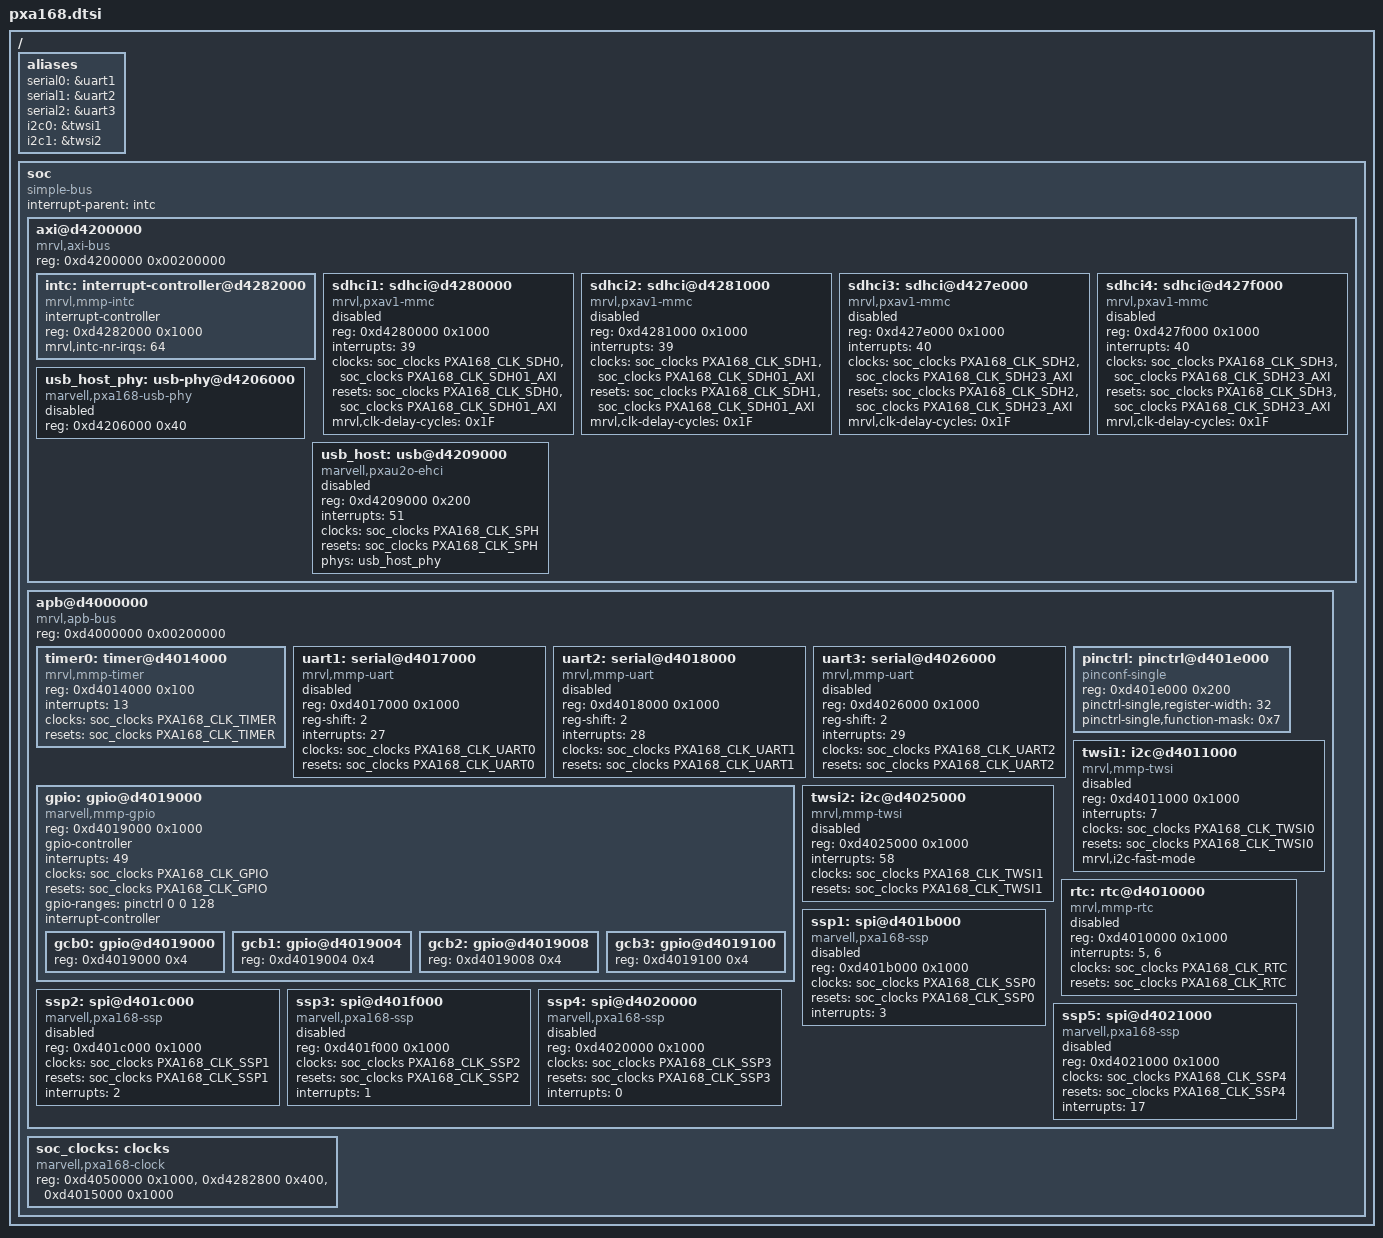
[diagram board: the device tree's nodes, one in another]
// SPDX-License-Identifier: GPL-2.0-only
/*
 *  Copyright (C) 2012 Marvell Technology Group Ltd.
 *  Author: Haojian Zhuang <haojian.zhuang@marvell.com>
 */

#include <dt-bindings/clock/marvell,pxa168.h>

#define MFP_PIN_PXA168(gpio)				\
	((gpio <= 36) ? (0x004c + 4 * gpio) :		\
	 (gpio <= 55) ? (0x0000 + 4 * (gpio - 37)) :	\
	 (gpio <= 122) ? (0x00e0 + 4 * (gpio - 56)) :	\
	 0)

#define MFP_AF0		(0 << 0)
#define MFP_AF1		(1 << 0)
#define MFP_AF2		(2 << 0)
#define MFP_AF3		(3 << 0)
#define MFP_AF4		(4 << 0)
#define MFP_AF5		(5 << 0)
#define MFP_AF6		(6 << 0)
#define MFP_AF7		(7 << 0)

#define MFP_DSMSK	(0x3 << 10)
#define MFP_DS01X	< (0x0 << 10) MFP_DSMSK >
#define MFP_DS02X	< (0x1 << 10) MFP_DSMSK >
#define MFP_DS03X	< (0x2 << 10) MFP_DSMSK >
#define MFP_DS04X	< (0x3 << 10) MFP_DSMSK >

#define MPF_PULL_MSK	(0x7 << 13)
#define MPF_PULL_DOWN	< (0x5 << 13) (0x5 << 13) 0 MPF_PULL_MSK >
#define MPF_PULL_UP	< (0x6 << 13) (0x6 << 13) 0 MPF_PULL_MSK >

/* TODO: MFP60 through MFP62's drive strength bits have special meaning for voltage control
 * MFP56 through MFP59's drive strength bits control all of MFP56 through MFP85 */

/ {
	#address-cells = <1>;
	#size-cells = <1>;

	aliases {
		serial0 = &uart1;
		serial1 = &uart2;
		serial2 = &uart3;
		i2c0 = &twsi1;
		i2c1 = &twsi2;
	};

	soc {
		#address-cells = <1>;
		#size-cells = <1>;
		compatible = "simple-bus";
		interrupt-parent = <&intc>;
		ranges;

		axi@d4200000 {	/* AXI */
			compatible = "mrvl,axi-bus", "simple-bus";
			#address-cells = <1>;
			#size-cells = <1>;
			reg = <0xd4200000 0x00200000>;
			ranges;

			intc: interrupt-controller@d4282000 {
				compatible = "mrvl,mmp-intc";
				interrupt-controller;
				#interrupt-cells = <1>;
				reg = <0xd4282000 0x1000>;
				mrvl,intc-nr-irqs = <64>;
			};

			sdhci1: sdhci@d4280000 {
				compatible = "mrvl,pxav1-mmc";
				reg = <0xd4280000 0x1000>;
				interrupts = <39>;
				clocks = <&soc_clocks PXA168_CLK_SDH0>,
					 <&soc_clocks PXA168_CLK_SDH01_AXI>;
				resets = <&soc_clocks PXA168_CLK_SDH0>,
					 <&soc_clocks PXA168_CLK_SDH01_AXI>;
				clock-names = "io", "core";
				mrvl,clk-delay-cycles = <0x1F>;
				status = "disabled";
			};

			sdhci2: sdhci@d4281000 {
				compatible = "mrvl,pxav1-mmc";
				reg = <0xd4281000 0x1000>;
				interrupts = <39>;
				clocks = <&soc_clocks PXA168_CLK_SDH1>,
					 <&soc_clocks PXA168_CLK_SDH01_AXI>;
				resets = <&soc_clocks PXA168_CLK_SDH1>,
					 <&soc_clocks PXA168_CLK_SDH01_AXI>;
				clock-names = "io", "core";
				mrvl,clk-delay-cycles = <0x1F>;
				status = "disabled";
			};

			sdhci3: sdhci@d427e000 {
				compatible = "mrvl,pxav1-mmc";
				reg = <0xd427e000 0x1000>;
				interrupts = <40>;
				clocks = <&soc_clocks PXA168_CLK_SDH2>,
					 <&soc_clocks PXA168_CLK_SDH23_AXI>;
				resets = <&soc_clocks PXA168_CLK_SDH2>,
					 <&soc_clocks PXA168_CLK_SDH23_AXI>;
				clock-names = "io", "core";
				mrvl,clk-delay-cycles = <0x1F>;
				status = "disabled";
			};

			sdhci4: sdhci@d427f000 {
				compatible = "mrvl,pxav1-mmc";
				reg = <0xd427f000 0x1000>;
				interrupts = <40>;
				clocks = <&soc_clocks PXA168_CLK_SDH3>,
					 <&soc_clocks PXA168_CLK_SDH23_AXI>;
				resets = <&soc_clocks PXA168_CLK_SDH3>,
					 <&soc_clocks PXA168_CLK_SDH23_AXI>;
				clock-names = "io", "core";
				mrvl,clk-delay-cycles = <0x1F>;
				status = "disabled";
			};

			usb_host_phy: usb-phy@d4206000 {
				compatible = "marvell,pxa168-usb-phy";
				reg = <0xd4206000 0x40>;
				#phy-cells = <0>;
				status = "disabled";
			};

			usb_host: usb@d4209000 {
				compatible = "marvell,pxau2o-ehci";
				reg = <0xd4209000 0x200>;
				interrupts = <51>;
				clocks = <&soc_clocks PXA168_CLK_SPH>;
				resets = <&soc_clocks PXA168_CLK_SPH>;
				clock-names = "USBCLK";
				phys = <&usb_host_phy>;
				phy-names = "usb";
				status = "disabled";
			};
		};

		apb@d4000000 {	/* APB */
			compatible = "mrvl,apb-bus", "simple-bus";
			#address-cells = <1>;
			#size-cells = <1>;
			reg = <0xd4000000 0x00200000>;
			ranges;

			timer0: timer@d4014000 {
				compatible = "mrvl,mmp-timer";
				reg = <0xd4014000 0x100>;
				interrupts = <13>;
				clocks = <&soc_clocks PXA168_CLK_TIMER>;
				resets = <&soc_clocks PXA168_CLK_TIMER>;
			};

			uart1: serial@d4017000 {
				compatible = "mrvl,mmp-uart", "intel,xscale-uart";
				reg = <0xd4017000 0x1000>;
				reg-shift = <2>;
				interrupts = <27>;
				clocks = <&soc_clocks PXA168_CLK_UART0>;
				resets = <&soc_clocks PXA168_CLK_UART0>;
				status = "disabled";
			};

			uart2: serial@d4018000 {
				compatible = "mrvl,mmp-uart", "intel,xscale-uart";
				reg = <0xd4018000 0x1000>;
				reg-shift = <2>;
				interrupts = <28>;
				clocks = <&soc_clocks PXA168_CLK_UART1>;
				resets = <&soc_clocks PXA168_CLK_UART1>;
				status = "disabled";
			};

			uart3: serial@d4026000 {
				compatible = "mrvl,mmp-uart", "intel,xscale-uart";
				reg = <0xd4026000 0x1000>;
				reg-shift = <2>;
				interrupts = <29>;
				clocks = <&soc_clocks PXA168_CLK_UART2>;
				resets = <&soc_clocks PXA168_CLK_UART2>;
				status = "disabled";
			};

			pinctrl: pinctrl@d401e000 {
				compatible = "pinconf-single";
				reg = <0xd401e000 0x200>;
				#pinctrl-cells = <1>;
				pinctrl-single,register-width = <32>;
				pinctrl-single,function-mask = <0x7>;
			};

			gpio: gpio@d4019000 {
				compatible = "marvell,mmp-gpio";
				#address-cells = <1>;
				#size-cells = <1>;
				reg = <0xd4019000 0x1000>;
				gpio-controller;
				#gpio-cells = <2>;
				interrupts = <49>;
				clocks = <&soc_clocks PXA168_CLK_GPIO>;
				resets = <&soc_clocks PXA168_CLK_GPIO>;
				gpio-ranges = <&pinctrl 0 0 128>;
				interrupt-names = "gpio_mux";
				interrupt-controller;
				#interrupt-cells = <2>;
				ranges;

				gcb0: gpio@d4019000 {
					reg = <0xd4019000 0x4>;
				};

				gcb1: gpio@d4019004 {
					reg = <0xd4019004 0x4>;
				};

				gcb2: gpio@d4019008 {
					reg = <0xd4019008 0x4>;
				};

				gcb3: gpio@d4019100 {
					reg = <0xd4019100 0x4>;
				};
			};

			twsi1: i2c@d4011000 {
				compatible = "mrvl,mmp-twsi";
				#address-cells = <1>;
				#size-cells = <0>;
				reg = <0xd4011000 0x1000>;
				interrupts = <7>;
				clocks = <&soc_clocks PXA168_CLK_TWSI0>;
				resets = <&soc_clocks PXA168_CLK_TWSI0>;
				mrvl,i2c-fast-mode;
				status = "disabled";
			};

			twsi2: i2c@d4025000 {
				compatible = "mrvl,mmp-twsi";
				#address-cells = <1>;
				#size-cells = <0>;
				reg = <0xd4025000 0x1000>;
				interrupts = <58>;
				clocks = <&soc_clocks PXA168_CLK_TWSI1>;
				resets = <&soc_clocks PXA168_CLK_TWSI1>;
				status = "disabled";
			};

			rtc: rtc@d4010000 {
				compatible = "mrvl,mmp-rtc";
				reg = <0xd4010000 0x1000>;
				interrupts = <5>, <6>;
				interrupt-names = "rtc 1Hz", "rtc alarm";
				clocks = <&soc_clocks PXA168_CLK_RTC>;
				resets = <&soc_clocks PXA168_CLK_RTC>;
				status = "disabled";
			};

			ssp1: spi@d401b000 {
				compatible = "marvell,pxa168-ssp";
				#address-cells = <1>;
				#size-cells = <0>;
				reg = <0xd401b000 0x1000>;
				clocks = <&soc_clocks PXA168_CLK_SSP0>;
				resets = <&soc_clocks PXA168_CLK_SSP0>;
				interrupts = <3>;
				status = "disabled";
			};

			ssp2: spi@d401c000 {
				compatible = "marvell,pxa168-ssp";
				#address-cells = <1>;
				#size-cells = <0>;
				reg = <0xd401c000 0x1000>;
				clocks = <&soc_clocks PXA168_CLK_SSP1>;
				resets = <&soc_clocks PXA168_CLK_SSP1>;
				interrupts = <2>;
				status = "disabled";
			};

			ssp3: spi@d401f000 {
				compatible = "marvell,pxa168-ssp";
				#address-cells = <1>;
				#size-cells = <0>;
				reg = <0xd401f000 0x1000>;
				clocks = <&soc_clocks PXA168_CLK_SSP2>;
				resets = <&soc_clocks PXA168_CLK_SSP2>;
				interrupts = <1>;
				status = "disabled";
			};

			ssp4: spi@d4020000 {
				compatible = "marvell,pxa168-ssp";
				#address-cells = <1>;
				#size-cells = <0>;
				reg = <0xd4020000 0x1000>;
				clocks = <&soc_clocks PXA168_CLK_SSP3>;
				resets = <&soc_clocks PXA168_CLK_SSP3>;
				interrupts = <0>;
				status = "disabled";
			};

			ssp5: spi@d4021000 {
				compatible = "marvell,pxa168-ssp";
				#address-cells = <1>;
				#size-cells = <0>;
				reg = <0xd4021000 0x1000>;
				clocks = <&soc_clocks PXA168_CLK_SSP4>;
				resets = <&soc_clocks PXA168_CLK_SSP4>;
				interrupts = <17>;
				status = "disabled";
			};
		};

		soc_clocks: clocks {
			compatible = "marvell,pxa168-clock";
			reg = <0xd4050000 0x1000>,
			      <0xd4282800 0x400>,
			      <0xd4015000 0x1000>;
			reg-names = "mpmu", "apmu", "apbc";
			#clock-cells = <1>;
			#reset-cells = <1>;
		};
	};
};
